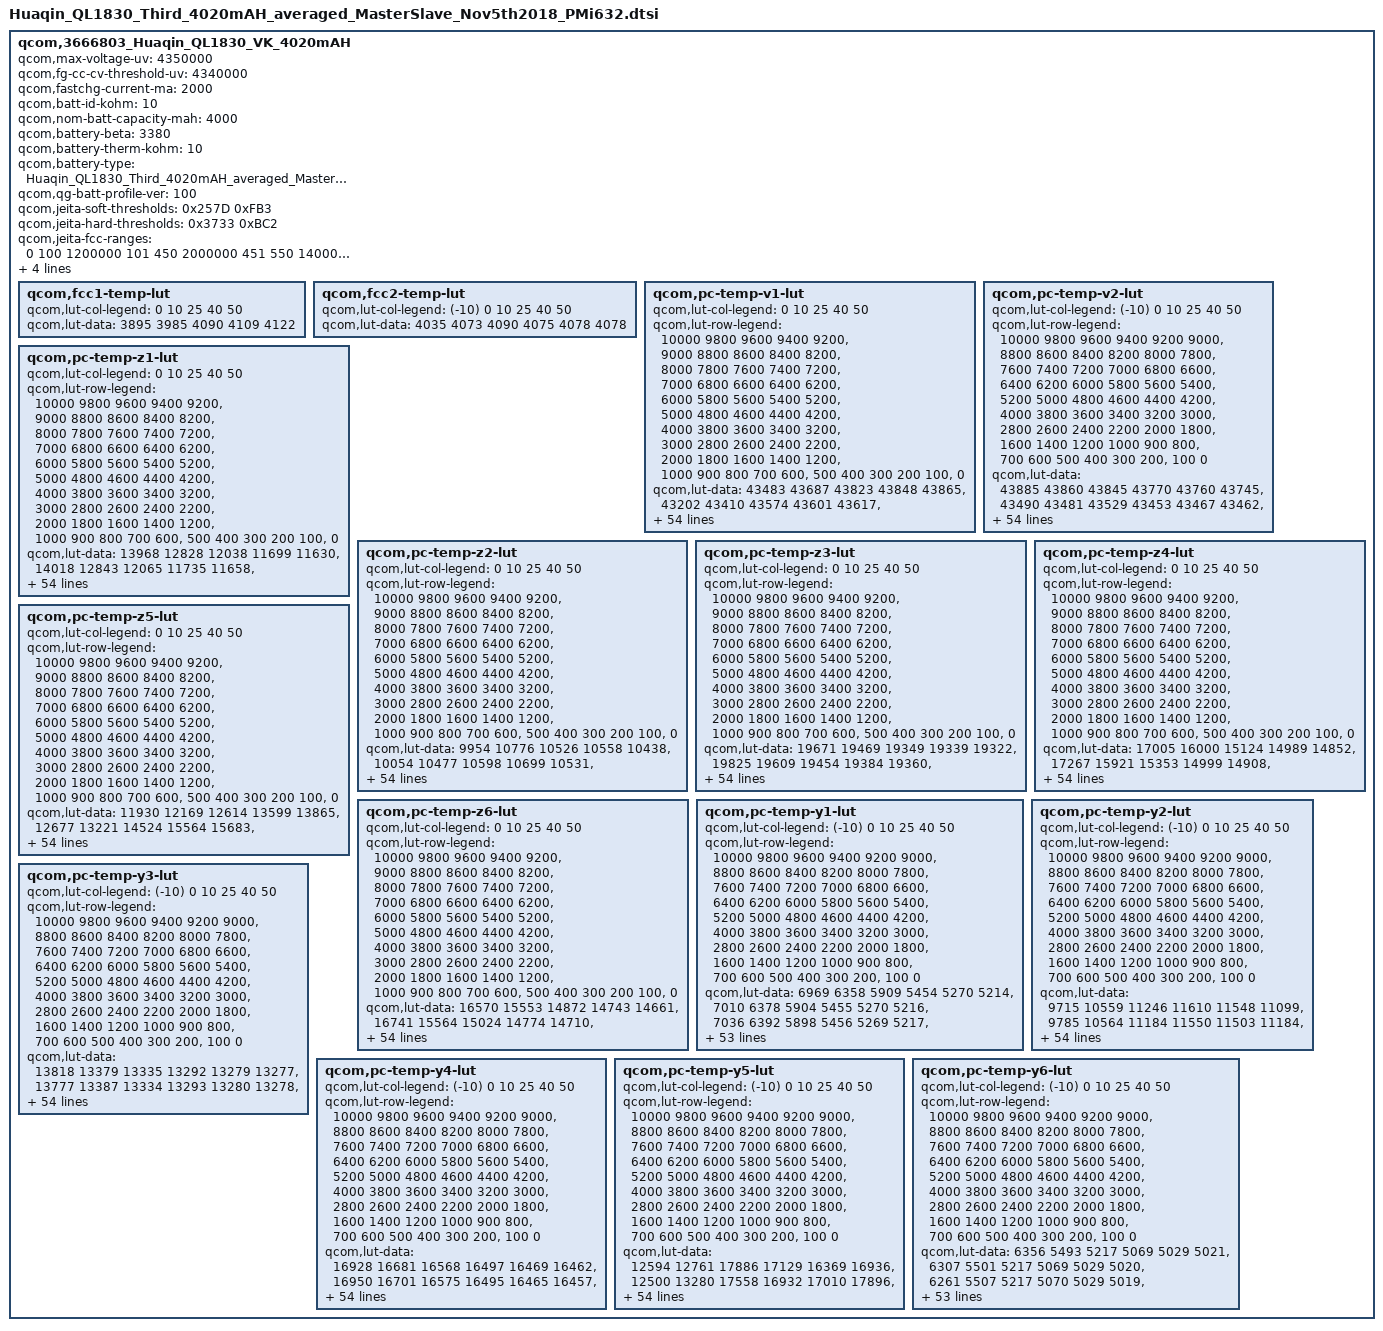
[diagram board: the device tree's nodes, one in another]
qcom,3666803_Huaqin_QL1830_VK_4020mAH {
    /* 3666803_Huaqin_QL1830_VK_4020mAH_averaged_MasterSlave_Nov5th2018 */
//huaqin add by wenyaqi for jeita and FV 4.35V at 20181105 start
    qcom,max-voltage-uv = <4350000>;
    qcom,fg-cc-cv-threshold-uv = <4340000>;
//huaqin add by wenyaqi for jeita and FV 4.35V at 20181105 end
    qcom,fastchg-current-ma = <2000>;
    qcom,batt-id-kohm = <10>;
    qcom,nom-batt-capacity-mah = <4000>;
    qcom,battery-beta = <3380>;
    qcom,battery-therm-kohm = <10>;
    qcom,battery-type = "Huaqin_QL1830_Third_4020mAH_averaged_MasterSlave_Nov5th2018";
    qcom,qg-batt-profile-ver = <100>;
//huaqin add by wenyaqi for jeita and FV 4.35V at 20181105 start
/* COOL = 15 DegC, WARM = 45 DegC */
    qcom,jeita-soft-thresholds = <0x257D 0xFB3>;
    /* COLD = 0 DegC, HOT = 55 DegC */
    qcom,jeita-hard-thresholds = <0x3733 0xBC2>;
    qcom,jeita-fcc-ranges = <0   100  1200000
                               101  450  2000000
                               451  550  1400000>;
    qcom,jeita-fv-ranges = <0   450  4350000
                            451 550  4100000>;
/*here step charge do not limit current*/
    qcom,step-chg-ranges = <3500000  4200000  2000000
                            4210000  4350000  2000000>;
//huaqin add by wenyaqi for jeita and FV 4.35V at 20181105 end

	qcom,fcc1-temp-lut {
		qcom,lut-col-legend = <0 10 25 40 50>;
		qcom,lut-data = <3895 3985 4090 4109 4122>;
	};

	qcom,fcc2-temp-lut {
		qcom,lut-col-legend = <(-10) 0 10 25 40 50>;
		qcom,lut-data = <4035 4073 4090 4075 4078 4078>;
	};

	qcom,pc-temp-v1-lut {
		qcom,lut-col-legend = <0 10 25 40 50>;
		qcom,lut-row-legend = <10000 9800 9600 9400 9200>,
			<9000 8800 8600 8400 8200>,
			<8000 7800 7600 7400 7200>,
			<7000 6800 6600 6400 6200>,
			<6000 5800 5600 5400 5200>,
			<5000 4800 4600 4400 4200>,
			<4000 3800 3600 3400 3200>,
			<3000 2800 2600 2400 2200>,
			<2000 1800 1600 1400 1200>,
			<1000 900 800 700 600>,
			<500 400 300 200 100>,
			<0>;
		qcom,lut-data = <43483 43687 43823 43848 43865>,
			<43202 43410 43574 43601 43617>,
			<42944 43147 43319 43352 43377>,
			<42701 42898 43068 43110 43137>,
			<42466 42660 42822 42871 42900>,
			<42241 42427 42579 42635 42665>,
			<42022 42198 42342 42401 42431>,
			<41807 41976 42110 42168 42198>,
			<41597 41757 41882 41937 41967>,
			<41401 41544 41655 41710 41739>,
			<41234 41348 41430 41485 41515>,
			<41060 41183 41224 41265 41295>,
			<40826 41005 41049 41051 41076>,
			<40527 40755 40866 40843 40864>,
			<40258 40452 40616 40634 40660>,
			<40039 40210 40331 40427 40464>,
			<39853 40026 40122 40235 40275>,
			<39713 39870 39979 40063 40095>,
			<39609 39740 39846 39900 39921>,
			<39509 39630 39701 39743 39757>,
			<39395 39509 39550 39588 39601>,
			<39280 39367 39389 39404 39420>,
			<39167 39218 39217 39153 39173>,
			<39056 39064 39034 38919 38936>,
			<38951 38905 38812 38764 38783>,
			<38855 38750 38598 38643 38666>,
			<38765 38590 38484 38542 38563>,
			<38680 38454 38416 38455 38468>,
			<38599 38371 38357 38373 38379>,
			<38523 38312 38294 38289 38289>,
			<38453 38266 38237 38210 38204>,
			<38386 38230 38185 38142 38130>,
			<38327 38199 38137 38083 38065>,
			<38278 38169 38092 38028 38005>,
			<38234 38143 38051 37978 37951>,
			<38191 38114 38012 37930 37900>,
			<38151 38084 37974 37884 37844>,
			<38108 38049 37938 37840 37787>,
			<38058 37997 37887 37784 37719>,
			<38001 37920 37802 37703 37637>,
			<37924 37827 37698 37605 37541>,
			<37805 37707 37588 37498 37434>,
			<37667 37569 37461 37375 37310>,
			<37512 37412 37304 37221 37157>,
			<37359 37277 37159 37077 37014>,
			<37244 37176 37073 36984 36923>,
			<37206 37143 37045 36956 36896>,
			<37176 37118 37032 36942 36881>,
			<37149 37095 37014 36925 36865>,
			<37107 37062 36974 36891 36829>,
			<36928 36894 36757 36709 36631>,
			<36497 36482 36337 36315 36234>,
			<35937 35934 35776 35783 35703>,
			<35180 35199 35012 35070 34992>,
			<33997 34069 33839 34011 33943>,
			<30000 30000 30000 30000 30000>;
	};

	qcom,pc-temp-v2-lut {
		qcom,lut-col-legend = <(-10) 0 10 25 40 50>;
		qcom,lut-row-legend = <10000 9800 9600 9400 9200 9000>,
			<8800 8600 8400 8200 8000 7800>,
			<7600 7400 7200 7000 6800 6600>,
			<6400 6200 6000 5800 5600 5400>,
			<5200 5000 4800 4600 4400 4200>,
			<4000 3800 3600 3400 3200 3000>,
			<2800 2600 2400 2200 2000 1800>,
			<1600 1400 1200 1000 900 800>,
			<700 600 500 400 300 200>,
			<100 0>;
		qcom,lut-data = <43885 43860 43845 43770 43760 43745>,
			<43490 43481 43529 43453 43467 43462>,
			<43135 43142 43234 43159 43192 43193>,
			<42823 42850 42963 42893 42934 42939>,
			<42548 42598 42714 42652 42694 42701>,
			<42294 42358 42474 42417 42459 42466>,
			<42064 42120 42238 42183 42225 42233>,
			<41843 41892 42008 41953 41994 42002>,
			<41593 41675 41785 41726 41766 41775>,
			<41306 41469 41568 41503 41541 41550>,
			<41089 41275 41356 41285 41320 41329>,
			<40986 41104 41153 41076 41102 41112>,
			<40897 40928 40954 40869 40889 40898>,
			<40689 40694 40762 40658 40685 40692>,
			<40236 40399 40574 40443 40487 40491>,
			<39838 40104 40346 40238 40295 40297>,
			<39602 39796 40022 40043 40106 40111>,
			<39412 39526 39718 39861 39925 39933>,
			<39248 39356 39530 39700 39759 39765>,
			<39104 39229 39385 39553 39601 39605>,
			<38961 39090 39227 39377 39421 39426>,
			<38813 38928 39051 39141 39196 39211>,
			<38669 38770 38883 38912 38977 38999>,
			<38534 38628 38737 38744 38797 38816>,
			<38404 38497 38604 38605 38638 38651>,
			<38291 38374 38484 38483 38507 38515>,
			<38197 38257 38374 38375 38398 38404>,
			<38116 38152 38273 38279 38301 38305>,
			<38046 38063 38181 38191 38212 38214>,
			<37985 37985 38094 38111 38130 38129>,
			<37929 37926 38013 38039 38057 38054>,
			<37877 37879 37934 37972 37990 37985>,
			<37828 37837 37866 37910 37926 37921>,
			<37778 37797 37811 37852 37860 37864>,
			<37729 37760 37764 37797 37795 37806>,
			<37679 37718 37723 37741 37724 37728>,
			<37626 37673 37688 37681 37647 37620>,
			<37572 37622 37647 37621 37568 37515>,
			<37516 37560 37593 37560 37489 37424>,
			<37459 37489 37531 37496 37409 37339>,
			<37399 37411 37460 37419 37328 37258>,
			<37338 37320 37374 37328 37245 37178>,
			<37272 37231 37260 37216 37139 37072>,
			<37200 37144 37130 37082 37009 36941>,
			<37115 37056 37011 36946 36873 36812>,
			<37007 36964 36939 36889 36822 36766>,
			<36943 36920 36910 36877 36810 36755>,
			<36870 36871 36890 36863 36800 36744>,
			<36787 36812 36864 36840 36778 36722>,
			<36669 36718 36798 36783 36731 36672>,
			<36477 36516 36602 36562 36535 36453>,
			<36156 36124 36167 36116 36113 36028>,
			<35658 35536 35562 35513 35547 35463>,
			<34904 34690 34727 34705 34792 34711>,
			<33674 33298 33484 33477 33679 33607>,
			<30842 29764 30363 29683 31836 31803>;
	};

	qcom,pc-temp-z1-lut {
		qcom,lut-col-legend = <0 10 25 40 50>;
		qcom,lut-row-legend = <10000 9800 9600 9400 9200>,
			<9000 8800 8600 8400 8200>,
			<8000 7800 7600 7400 7200>,
			<7000 6800 6600 6400 6200>,
			<6000 5800 5600 5400 5200>,
			<5000 4800 4600 4400 4200>,
			<4000 3800 3600 3400 3200>,
			<3000 2800 2600 2400 2200>,
			<2000 1800 1600 1400 1200>,
			<1000 900 800 700 600>,
			<500 400 300 200 100>,
			<0>;
		qcom,lut-data = <13968 12828 12038 11699 11630>,
			<14018 12843 12065 11735 11658>,
			<14014 12850 12067 11739 11663>,
			<14002 12846 12068 11743 11665>,
			<14002 12838 12066 11743 11666>,
			<14005 12837 12060 11742 11666>,
			<13996 12852 12056 11741 11667>,
			<13976 12865 12055 11741 11668>,
			<13952 12859 12054 11742 11671>,
			<13939 12846 12055 11742 11672>,
			<13937 12841 12059 11744 11672>,
			<13935 12843 12063 11745 11672>,
			<13916 12842 12067 11747 11673>,
			<13860 12819 12069 11748 11674>,
			<13803 12778 12058 11747 11675>,
			<13747 12762 12036 11745 11676>,
			<13699 12761 12030 11745 11676>,
			<13682 12762 12040 11747 11677>,
			<13678 12771 12051 11750 11678>,
			<13673 12789 12058 11751 11680>,
			<13657 12803 12063 11752 11681>,
			<13637 12815 12068 11753 11682>,
			<13636 12825 12072 11754 11683>,
			<13676 12828 12076 11755 11683>,
			<13714 12828 12081 11757 11685>,
			<13714 12831 12085 11759 11687>,
			<13702 12844 12089 11762 11689>,
			<13701 12856 12092 11765 11692>,
			<13713 12862 12096 11768 11695>,
			<13730 12872 12101 11772 11698>,
			<13758 12880 12107 11776 11701>,
			<13805 12892 12111 11780 11704>,
			<13829 12904 12115 11784 11706>,
			<13810 12906 12119 11788 11708>,
			<13782 12903 12129 11791 11710>,
			<13778 12902 12140 11794 11712>,
			<13792 12911 12147 11796 11714>,
			<13813 12925 12152 11798 11716>,
			<13844 12933 12158 11801 11718>,
			<13885 12949 12163 11804 11720>,
			<13909 12961 12169 11807 11722>,
			<13913 12973 12174 11810 11723>,
			<13911 12981 12179 11813 11725>,
			<13917 12956 12190 11816 11727>,
			<13923 12975 12195 11819 11728>,
			<13849 12983 12200 11821 11729>,
			<13896 12980 12198 11822 11730>,
			<13868 12969 12196 11823 11730>,
			<13832 12981 12195 11824 11732>,
			<13841 12976 12207 11827 11734>,
			<13892 13007 12214 11832 11737>,
			<13865 12986 12222 11840 11742>,
			<13935 13026 12248 11851 11751>,
			<13903 13104 12270 11866 11763>,
			<13903 13104 12270 11866 11763>,
			<13903 13104 12270 11866 11763>;
	};

	qcom,pc-temp-z2-lut {
		qcom,lut-col-legend = <0 10 25 40 50>;
		qcom,lut-row-legend = <10000 9800 9600 9400 9200>,
			<9000 8800 8600 8400 8200>,
			<8000 7800 7600 7400 7200>,
			<7000 6800 6600 6400 6200>,
			<6000 5800 5600 5400 5200>,
			<5000 4800 4600 4400 4200>,
			<4000 3800 3600 3400 3200>,
			<3000 2800 2600 2400 2200>,
			<2000 1800 1600 1400 1200>,
			<1000 900 800 700 600>,
			<500 400 300 200 100>,
			<0>;
		qcom,lut-data = <9954 10776 10526 10558 10438>,
			<10054 10477 10598 10699 10531>,
			<10110 10321 10609 10804 10678>,
			<10154 10311 10589 10775 10695>,
			<10167 10303 10555 10729 10681>,
			<10168 10302 10513 10663 10632>,
			<10166 10312 10507 10615 10595>,
			<10159 10321 10609 10596 10592>,
			<10147 10315 10688 10585 10593>,
			<10139 10300 10618 10589 10594>,
			<10134 10289 10499 10610 10594>,
			<10130 10282 10506 10634 10595>,
			<10123 10274 10668 10659 10601>,
			<10113 10256 10780 10678 10608>,
			<10102 10229 10703 10679 10597>,
			<10084 10221 10577 10672 10538>,
			<10064 10227 10555 10661 10502>,
			<10056 10238 10575 10611 10512>,
			<10054 10256 10604 10559 10533>,
			<10052 10286 10631 10562 10556>,
			<10051 10314 10661 10587 10585>,
			<10050 10339 10698 10639 10637>,
			<10049 10364 10751 10808 10794>,
			<10051 10399 10781 10934 10922>,
			<10053 10442 10746 10824 10854>,
			<10055 10463 10699 10616 10692>,
			<10057 10468 10687 10572 10652>,
			<10061 10471 10681 10616 10711>,
			<10072 10480 10686 10679 10756>,
			<10087 10497 10724 10783 10745>,
			<10107 10505 10766 10893 10720>,
			<10137 10503 10772 10891 10691>,
			<10160 10500 10769 10801 10640>,
			<10169 10502 10769 10753 10612>,
			<10179 10510 10776 10788 10616>,
			<10188 10521 10788 10851 10625>,
			<10197 10532 10802 10909 10676>,
			<10201 10547 10821 10975 10850>,
			<10086 10565 10841 11026 10966>,
			<9844 10588 10873 11068 11005>,
			<9764 10611 10902 11093 11026>,
			<9813 10629 10914 11088 11010>,
			<9842 10650 10924 11076 10951>,
			<9841 10691 10941 11092 10910>,
			<9846 10691 11021 11085 10887>,
			<9849 10689 11119 11045 10846>,
			<9822 10717 11109 11022 10851>,
			<9832 10785 11160 10977 10866>,
			<9824 10773 11290 10978 10888>,
			<9781 10777 11257 11067 11125>,
			<9773 10786 11304 11171 10980>,
			<9739 10657 11239 11020 10654>,
			<9630 10446 11233 10912 10546>,
			<9519 10284 11171 10811 10499>,
			<9519 10284 11171 10811 10499>,
			<9519 10284 11171 10811 10499>;
	};

	qcom,pc-temp-z3-lut {
		qcom,lut-col-legend = <0 10 25 40 50>;
		qcom,lut-row-legend = <10000 9800 9600 9400 9200>,
			<9000 8800 8600 8400 8200>,
			<8000 7800 7600 7400 7200>,
			<7000 6800 6600 6400 6200>,
			<6000 5800 5600 5400 5200>,
			<5000 4800 4600 4400 4200>,
			<4000 3800 3600 3400 3200>,
			<3000 2800 2600 2400 2200>,
			<2000 1800 1600 1400 1200>,
			<1000 900 800 700 600>,
			<500 400 300 200 100>,
			<0>;
		qcom,lut-data = <19671 19469 19349 19339 19322>,
			<19825 19609 19454 19384 19360>,
			<19827 19687 19498 19426 19390>,
			<19825 19696 19520 19440 19403>,
			<19822 19700 19525 19443 19408>,
			<19812 19700 19527 19442 19411>,
			<19804 19683 19530 19439 19413>,
			<19804 19665 19534 19435 19412>,
			<19807 19657 19532 19430 19408>,
			<19810 19651 19514 19422 19403>,
			<19814 19642 19486 19409 19394>,
			<19819 19616 19477 19399 19386>,
			<19828 19594 19478 19394 19382>,
			<19843 19605 19477 19390 19379>,
			<19850 19632 19472 19388 19372>,
			<19836 19640 19463 19387 19360>,
			<19809 19609 19454 19384 19350>,
			<19783 19572 19437 19370 19346>,
			<19755 19553 19422 19355 19343>,
			<19731 19538 19413 19350 19341>,
			<19712 19534 19407 19348 19340>,
			<19696 19541 19410 19350 19340>,
			<19687 19553 19432 19371 19351>,
			<19682 19568 19449 19388 19362>,
			<19679 19587 19450 19380 19353>,
			<19674 19597 19451 19360 19331>,
			<19668 19601 19448 19348 19324>,
			<19668 19603 19435 19340 19325>,
			<19674 19602 19426 19337 19328>,
			<19681 19598 19425 19356 19346>,
			<19691 19592 19425 19386 19374>,
			<19721 19585 19428 19391 19379>,
			<19738 19578 19435 19387 19371>,
			<19733 19570 19439 19382 19363>,
			<19726 19563 19438 19378 19354>,
			<19716 19555 19438 19373 19346>,
			<19700 19545 19436 19369 19344>,
			<19673 19536 19429 19364 19344>,
			<19591 19529 19424 19361 19343>,
			<19460 19524 19422 19358 19341>,
			<19415 19519 19420 19355 19339>,
			<19416 19514 19416 19353 19338>,
			<19414 19507 19410 19351 19337>,
			<19390 19491 19407 19350 19337>,
			<19361 19397 19398 19344 19336>,
			<19352 19339 19377 19337 19330>,
			<19347 19317 19373 19338 19329>,
			<19341 19306 19330 19328 19322>,
			<19338 19301 19315 19327 19317>,
			<19334 19298 19318 19320 19305>,
			<19336 19304 19339 19316 19317>,
			<19353 19311 19323 19321 19329>,
			<19369 19314 19317 19322 19330>,
			<19376 19312 19306 19319 19329>,
			<19376 19312 19306 19319 19329>,
			<19376 19312 19306 19319 19329>;
	};

	qcom,pc-temp-z4-lut {
		qcom,lut-col-legend = <0 10 25 40 50>;
		qcom,lut-row-legend = <10000 9800 9600 9400 9200>,
			<9000 8800 8600 8400 8200>,
			<8000 7800 7600 7400 7200>,
			<7000 6800 6600 6400 6200>,
			<6000 5800 5600 5400 5200>,
			<5000 4800 4600 4400 4200>,
			<4000 3800 3600 3400 3200>,
			<3000 2800 2600 2400 2200>,
			<2000 1800 1600 1400 1200>,
			<1000 900 800 700 600>,
			<500 400 300 200 100>,
			<0>;
		qcom,lut-data = <17005 16000 15124 14989 14852>,
			<17267 15921 15353 14999 14908>,
			<17095 15814 15273 15005 14924>,
			<16737 15660 15133 14937 14884>,
			<16444 15471 15044 14887 14847>,
			<16195 15338 14975 14850 14817>,
			<15985 15246 14914 14820 14789>,
			<15829 15171 14854 14792 14763>,
			<15704 15108 14816 14767 14740>,
			<15590 15054 14807 14753 14729>,
			<15475 15011 14801 14745 14723>,
			<15379 14978 14789 14737 14718>,
			<15323 14947 14753 14729 14709>,
			<15287 14909 14728 14720 14699>,
			<15250 14870 14738 14710 14696>,
			<15206 14851 14757 14701 14696>,
			<15162 14845 14756 14696 14694>,
			<15124 14840 14738 14696 14689>,
			<15086 14829 14724 14697 14682>,
			<15060 14811 14724 14695 14677>,
			<15050 14795 14726 14692 14673>,
			<15043 14779 14726 14695 14674>,
			<15037 14768 14725 14740 14726>,
			<15030 14767 14724 14794 14791>,
			<15024 14770 14774 14824 14818>,
			<15019 14776 14849 14845 14837>,
			<15018 14810 14859 14848 14838>,
			<15013 14845 14847 14838 14821>,
			<15000 14845 14831 14822 14794>,
			<14983 14835 14814 14783 14754>,
			<14961 14824 14794 14733 14708>,
			<14919 14810 14772 14710 14690>,
			<14886 14795 14749 14698 14682>,
			<14871 14782 14732 14693 14680>,
			<14860 14768 14720 14692 14681>,
			<14856 14758 14711 14691 14684>,
			<14854 14750 14708 14692 14687>,
			<14853 14743 14705 14695 14693>,
			<14909 14738 14705 14701 14699>,
			<15029 14735 14714 14713 14708>,
			<15069 14732 14722 14723 14716>,
			<15044 14729 14717 14719 14713>,
			<15024 14728 14709 14710 14706>,
			<15015 14731 14708 14712 14708>,
			<14942 14774 14698 14708 14704>,
			<14910 14802 14677 14684 14682>,
			<14912 14821 14670 14673 14672>,
			<14910 14823 14703 14664 14660>,
			<14907 14822 14709 14644 14641>,
			<14903 14821 14701 14645 14643>,
			<14897 14817 14701 14679 14664>,
			<14912 14832 14731 14688 14667>,
			<14922 14842 14745 14691 14668>,
			<14942 14859 14763 14697 14670>,
			<14942 14859 14763 14697 14670>,
			<14942 14859 14763 14697 14670>;
	};

	qcom,pc-temp-z5-lut {
		qcom,lut-col-legend = <0 10 25 40 50>;
		qcom,lut-row-legend = <10000 9800 9600 9400 9200>,
			<9000 8800 8600 8400 8200>,
			<8000 7800 7600 7400 7200>,
			<7000 6800 6600 6400 6200>,
			<6000 5800 5600 5400 5200>,
			<5000 4800 4600 4400 4200>,
			<4000 3800 3600 3400 3200>,
			<3000 2800 2600 2400 2200>,
			<2000 1800 1600 1400 1200>,
			<1000 900 800 700 600>,
			<500 400 300 200 100>,
			<0>;
		qcom,lut-data = <11930 12169 12614 13599 13865>,
			<12677 13221 14524 15564 15683>,
			<13207 13962 15397 17286 17114>,
			<13651 14363 16009 18157 18103>,
			<14101 14645 16513 18572 18776>,
			<14558 14830 17016 18734 19288>,
			<14982 14962 17603 18786 19825>,
			<15351 15118 18733 19046 20743>,
			<15690 15453 19464 19548 21746>,
			<16074 15882 19002 19619 21899>,
			<16548 15992 18334 19232 21284>,
			<17079 15786 18731 18993 20849>,
			<17679 15611 21556 19256 21301>,
			<18380 16803 23424 19794 22020>,
			<18742 19623 22471 20584 21816>,
			<18772 20525 21071 21711 20206>,
			<18772 18971 20372 22055 19235>,
			<18730 17441 19810 20519 19505>,
			<18582 17454 19582 18913 20045>,
			<18435 17890 19730 18886 20669>,
			<18195 18551 20148 19337 21552>,
			<17752 20494 22252 21376 23224>,
			<17421 23715 31855 33091 29060>,
			<17310 29446 38374 42461 34247>,
			<17274 38549 38478 36827 30498>,
			<17190 43375 38321 24864 20805>,
			<17121 45003 36460 19381 16607>,
			<17363 45916 29311 16856 15428>,
			<18140 45070 24481 15848 14948>,
			<18856 41664 23165 17608 17169>,
			<19401 38426 22443 21079 21626>,
			<21226 35882 22891 23469 24154>,
			<22404 33656 25093 25268 25774>,
			<22365 32055 27686 27132 26626>,
			<22275 30816 31201 29811 26848>,
			<22019 29666 34076 31939 27000>,
			<21076 28282 34460 31916 27297>,
			<19664 27165 34079 30986 27892>,
			<17024 27081 33792 29683 28069>,
			<13434 27730 32927 27094 25577>,
			<12288 28004 31772 24524 22670>,
			<12492 27610 30322 23468 21879>,
			<12580 26857 28563 22819 21417>,
			<12418 24782 27887 22117 21042>,
			<12763 17697 28265 21957 21095>,
			<12829 14069 25887 22222 21119>,
			<12644 13088 24813 23104 21642>,
			<12523 12749 16311 21033 20706>,
			<12467 12603 14629 23240 23048>,
			<12436 12561 15128 21990 20033>,
			<12628 12908 17024 17321 18232>,
			<12862 12895 14717 15758 17521>,
			<12821 12787 13893 15145 16698>,
			<12561 12409 13030 14401 15896>,
			<12561 12409 13030 14401 15896>,
			<12561 12409 13030 14401 15896>;
	};

	qcom,pc-temp-z6-lut {
		qcom,lut-col-legend = <0 10 25 40 50>;
		qcom,lut-row-legend = <10000 9800 9600 9400 9200>,
			<9000 8800 8600 8400 8200>,
			<8000 7800 7600 7400 7200>,
			<7000 6800 6600 6400 6200>,
			<6000 5800 5600 5400 5200>,
			<5000 4800 4600 4400 4200>,
			<4000 3800 3600 3400 3200>,
			<3000 2800 2600 2400 2200>,
			<2000 1800 1600 1400 1200>,
			<1000 900 800 700 600>,
			<500 400 300 200 100>,
			<0>;
		qcom,lut-data = <16570 15553 14872 14743 14661>,
			<16741 15564 15024 14774 14710>,
			<16660 15566 15007 14795 14729>,
			<16488 15524 14966 14778 14722>,
			<16345 15426 14933 14762 14713>,
			<16219 15354 14903 14745 14702>,
			<16112 15302 14877 14730 14691>,
			<16035 15259 14855 14716 14680>,
			<15974 15224 14836 14703 14669>,
			<15919 15196 14820 14692 14660>,
			<15868 15168 14806 14682 14653>,
			<15821 15138 14794 14673 14646>,
			<15781 15112 14780 14667 14640>,
			<15746 15096 14771 14661 14635>,
			<15710 15084 14768 14656 14628>,
			<15667 15070 14766 14651 14622>,
			<15624 15051 14762 14646 14616>,
			<15588 15033 14746 14638 14611>,
			<15556 15020 14734 14631 14606>,
			<15532 15009 14730 14627 14603>,
			<15518 15005 14729 14625 14601>,
			<15508 15006 14729 14628 14602>,
			<15504 15007 14738 14660 14632>,
			<15504 15011 14751 14691 14664>,
			<15505 15024 14778 14696 14669>,
			<15508 15037 14808 14697 14668>,
			<15513 15057 14811 14695 14665>,
			<15517 15073 14800 14687 14658>,
			<15519 15073 14790 14679 14651>,
			<15520 15068 14783 14673 14645>,
			<15521 15062 14776 14668 14640>,
			<15523 15055 14770 14662 14634>,
			<15524 15047 14764 14655 14628>,
			<15521 15039 14759 14650 14622>,
			<15515 15031 14756 14647 14617>,
			<15511 15025 14753 14644 14614>,
			<15508 15020 14749 14643 14614>,
			<15505 15016 14746 14642 14616>,
			<15499 15015 14745 14642 14618>,
			<15491 15015 14749 14645 14621>,
			<15485 15014 14753 14649 14623>,
			<15481 15015 14750 14647 14622>,
			<15475 15015 14745 14642 14619>,
			<15462 15011 14744 14643 14620>,
			<15417 14987 14738 14639 14617>,
			<15397 14971 14719 14625 14604>,
			<15395 14968 14714 14621 14600>,
			<15390 14965 14707 14612 14591>,
			<15392 14963 14701 14603 14581>,
			<15394 14963 14702 14599 14575>,
			<15398 14973 14714 14612 14591>,
			<15424 14988 14722 14622 14600>,
			<15452 15007 14730 14626 14604>,
			<15484 15028 14740 14631 14607>,
			<15484 15028 14740 14631 14607>,
			<15484 15028 14740 14631 14607>;
	};

	qcom,pc-temp-y1-lut {
		qcom,lut-col-legend = <(-10) 0 10 25 40 50>;
		qcom,lut-row-legend = <10000 9800 9600 9400 9200 9000>,
			<8800 8600 8400 8200 8000 7800>,
			<7600 7400 7200 7000 6800 6600>,
			<6400 6200 6000 5800 5600 5400>,
			<5200 5000 4800 4600 4400 4200>,
			<4000 3800 3600 3400 3200 3000>,
			<2800 2600 2400 2200 2000 1800>,
			<1600 1400 1200 1000 900 800>,
			<700 600 500 400 300 200>,
			<100 0>;
		qcom,lut-data = <6969 6358 5909 5454 5270 5214>,
			<7010 6378 5904 5455 5270 5216>,
			<7036 6392 5898 5456 5269 5217>,
			<7052 6401 5893 5456 5268 5218>,
			<7058 6406 5888 5455 5267 5219>,
			<7059 6407 5886 5454 5267 5219>,
			<7047 6401 5884 5453 5265 5219>,
			<7031 6393 5883 5451 5263 5218>,
			<7034 6390 5882 5450 5263 5218>,
			<7063 6391 5882 5449 5264 5218>,
			<7081 6391 5881 5448 5264 5218>,
			<7070 6388 5874 5447 5264 5218>,
			<7055 6385 5867 5446 5264 5218>,
			<7053 6385 5865 5446 5264 5218>,
			<7057 6389 5864 5446 5264 5218>,
			<7060 6393 5864 5447 5264 5219>,
			<7059 6405 5878 5454 5266 5220>,
			<7057 6420 5890 5460 5267 5221>,
			<7054 6425 5890 5460 5267 5221>,
			<7050 6431 5887 5458 5267 5221>,
			<7046 6430 5884 5458 5267 5221>,
			<7034 6415 5882 5461 5269 5223>,
			<7023 6401 5880 5464 5271 5224>,
			<7038 6395 5880 5466 5272 5225>,
			<7079 6388 5881 5467 5273 5226>,
			<7097 6385 5882 5469 5275 5227>,
			<7068 6389 5886 5471 5276 5228>,
			<7030 6394 5891 5474 5277 5230>,
			<7020 6406 5893 5478 5280 5232>,
			<7016 6423 5896 5482 5282 5233>,
			<7016 6423 5896 5486 5285 5235>,
			<7033 6407 5894 5490 5287 5236>,
			<7052 6397 5894 5492 5289 5238>,
			<7043 6394 5897 5494 5292 5240>,
			<7015 6390 5900 5496 5295 5242>,
			<7004 6394 5899 5499 5297 5244>,
			<7006 6403 5899 5504 5298 5246>,
			<7012 6407 5900 5508 5299 5247>,
			<7016 6398 5899 5509 5301 5248>,
			<7022 6389 5899 5510 5303 5249>,
			<7027 6391 5908 5513 5304 5250>,
			<7034 6393 5925 5517 5305 5252>,
			<7024 6403 5922 5519 5307 5253>,
			<7006 6419 5915 5523 5310 5255>,
			<7020 6430 5939 5533 5314 5258>,
			<7102 6445 5939 5540 5318 5260>,
			<7069 6457 5936 5538 5319 5260>,
			<7097 6432 5944 5543 5319 5261>,
			<7083 6439 5960 5548 5320 5260>,
			<7072 6458 5958 5547 5319 5261>,
			<7074 6461 5957 5551 5320 5261>,
			<7129 6457 5970 5562 5325 5265>,
			<7121 6481 5969 5578 5332 5270>,
			<7233 6528 6001 5598 5342 5277>,
			<7233 6528 6001 5598 5342 5277>,
			<7233 6528 6001 5598 5342 5277>;
	};

	qcom,pc-temp-y2-lut {
		qcom,lut-col-legend = <(-10) 0 10 25 40 50>;
		qcom,lut-row-legend = <10000 9800 9600 9400 9200 9000>,
			<8800 8600 8400 8200 8000 7800>,
			<7600 7400 7200 7000 6800 6600>,
			<6400 6200 6000 5800 5600 5400>,
			<5200 5000 4800 4600 4400 4200>,
			<4000 3800 3600 3400 3200 3000>,
			<2800 2600 2400 2200 2000 1800>,
			<1600 1400 1200 1000 900 800>,
			<700 600 500 400 300 200>,
			<100 0>;
		qcom,lut-data = <9715 10559 11246 11610 11548 11099>,
			<9785 10564 11184 11550 11503 11184>,
			<9854 10572 11119 11492 11442 11229>,
			<9920 10583 11056 11437 11378 11246>,
			<9980 10597 11004 11386 11329 11244>,
			<10032 10613 10969 11342 11308 11234>,
			<10070 10638 10943 11297 11310 11191>,
			<10109 10660 10927 11259 11314 11142>,
			<10186 10656 10927 11243 11304 11140>,
			<10339 10630 10933 11232 11276 11154>,
			<10468 10618 10937 11223 11259 11163>,
			<10554 10741 10932 11209 11259 11152>,
			<10624 10906 10929 11197 11261 11136>,
			<10657 10944 10978 11207 11260 11133>,
			<10690 10929 11110 11251 11266 11137>,
			<10720 10914 11162 11291 11286 11156>,
			<10743 10914 11156 11318 11354 11226>,
			<10762 10921 11150 11347 11441 11318>,
			<10726 10946 11161 11410 11525 11404>,
			<10488 10986 11190 11502 11614 11493>,
			<10314 11017 11216 11531 11649 11547>,
			<10294 11040 11241 11504 11645 11585>,
			<10278 11060 11265 11477 11630 11606>,
			<10168 11082 11286 11491 11584 11560>,
			<9860 11103 11304 11528 11515 11455>,
			<9714 11109 11317 11550 11504 11426>,
			<9697 11102 11327 11562 11561 11469>,
			<9688 11096 11339 11573 11637 11531>,
			<9683 11110 11356 11595 11709 11609>,
			<9680 11137 11373 11624 11781 11713>,
			<9678 11142 11380 11642 11830 11801>,
			<9676 11126 11382 11657 11871 11878>,
			<9674 11103 11380 11666 11889 11951>,
			<9672 11077 11376 11656 11873 12053>,
			<9670 11043 11369 11635 11843 12139>,
			<9668 10973 11356 11618 11809 12079>,
			<9666 10655 11331 11604 11749 11774>,
			<9665 10365 11307 11591 11716 11564>,
			<9663 10069 11285 11573 11725 11517>,
			<9662 9745 11259 11554 11736 11493>,
			<9661 9690 11225 11542 11733 11514>,
			<9660 9677 11181 11535 11706 11586>,
			<9660 9670 11123 11515 11665 11610>,
			<9659 9665 11034 11451 11649 11577>,
			<9658 9663 10984 11448 11565 11454>,
			<9659 9662 10881 11374 11413 11205>,
			<9658 9660 10821 11382 11367 11219>,
			<9658 9659 10773 11347 11393 11265>,
			<9657 9658 10761 11352 11391 11297>,
			<9657 9657 10734 11345 11403 11303>,
			<9657 9656 10556 11323 11432 11225>,
			<9656 9656 10226 11253 11320 11114>,
			<9654 9655 10083 11102 11244 10966>,
			<9653 9653 9697 10992 11129 10962>,
			<9653 9653 9697 10992 11129 10962>,
			<9653 9653 9697 10992 11129 10962>;
	};

	qcom,pc-temp-y3-lut {
		qcom,lut-col-legend = <(-10) 0 10 25 40 50>;
		qcom,lut-row-legend = <10000 9800 9600 9400 9200 9000>,
			<8800 8600 8400 8200 8000 7800>,
			<7600 7400 7200 7000 6800 6600>,
			<6400 6200 6000 5800 5600 5400>,
			<5200 5000 4800 4600 4400 4200>,
			<4000 3800 3600 3400 3200 3000>,
			<2800 2600 2400 2200 2000 1800>,
			<1600 1400 1200 1000 900 800>,
			<700 600 500 400 300 200>,
			<100 0>;
		qcom,lut-data = <13818 13379 13335 13292 13279 13277>,
			<13777 13387 13334 13293 13280 13278>,
			<13738 13397 13335 13294 13281 13279>,
			<13701 13407 13336 13295 13283 13280>,
			<13669 13416 13338 13296 13284 13281>,
			<13642 13422 13340 13297 13285 13282>,
			<13621 13425 13343 13298 13286 13283>,
			<13604 13427 13347 13299 13287 13284>,
			<13590 13432 13349 13299 13288 13285>,
			<13577 13443 13351 13300 13289 13286>,
			<13560 13450 13353 13301 13289 13286>,
			<13514 13451 13356 13305 13289 13287>,
			<13465 13447 13358 13308 13289 13287>,
			<13460 13437 13360 13309 13291 13287>,
			<13473 13417 13363 13309 13294 13287>,
			<13480 13401 13364 13310 13296 13287>,
			<13457 13389 13357 13310 13296 13289>,
			<13426 13382 13349 13311 13296 13291>,
			<13419 13382 13345 13312 13295 13291>,
			<13419 13384 13342 13314 13295 13292>,
			<13419 13384 13339 13314 13293 13292>,
			<13416 13379 13334 13308 13291 13288>,
			<13414 13373 13329 13300 13288 13284>,
			<13413 13367 13326 13296 13284 13281>,
			<13408 13361 13323 13293 13280 13277>,
			<13404 13355 13322 13292 13278 13276>,
			<13406 13351 13322 13292 13278 13276>,
			<13407 13345 13321 13292 13278 13276>,
			<13406 13338 13322 13293 13278 13276>,
			<13405 13330 13322 13295 13279 13275>,
			<13407 13327 13322 13296 13280 13276>,
			<13413 13330 13320 13297 13281 13276>,
			<13421 13333 13319 13298 13282 13277>,
			<13433 13337 13320 13298 13282 13278>,
			<13453 13343 13320 13298 13282 13279>,
			<13475 13349 13322 13298 13281 13279>,
			<13503 13355 13325 13297 13282 13278>,
			<13537 13363 13327 13296 13282 13276>,
			<13580 13373 13329 13297 13281 13276>,
			<13631 13385 13331 13297 13281 13275>,
			<13686 13398 13332 13297 13282 13276>,
			<13748 13412 13334 13298 13282 13279>,
			<13813 13441 13334 13298 13282 13279>,
			<13879 13499 13330 13296 13282 13277>,
			<13939 13550 13320 13292 13279 13275>,
			<13862 13571 13324 13293 13282 13281>,
			<13931 13636 13327 13297 13283 13282>,
			<14004 13705 13339 13301 13289 13287>,
			<14072 13796 13352 13307 13292 13289>,
			<14148 13872 13361 13311 13295 13292>,
			<14219 13956 13364 13306 13291 13286>,
			<14312 14042 13367 13307 13285 13285>,
			<14566 14156 13398 13312 13289 13286>,
			<14994 14378 13466 13324 13297 13293>,
			<14994 14378 13466 13324 13297 13293>,
			<14994 14378 13466 13324 13297 13293>;
	};

	qcom,pc-temp-y4-lut {
		qcom,lut-col-legend = <(-10) 0 10 25 40 50>;
		qcom,lut-row-legend = <10000 9800 9600 9400 9200 9000>,
			<8800 8600 8400 8200 8000 7800>,
			<7600 7400 7200 7000 6800 6600>,
			<6400 6200 6000 5800 5600 5400>,
			<5200 5000 4800 4600 4400 4200>,
			<4000 3800 3600 3400 3200 3000>,
			<2800 2600 2400 2200 2000 1800>,
			<1600 1400 1200 1000 900 800>,
			<700 600 500 400 300 200>,
			<100 0>;
		qcom,lut-data = <16928 16681 16568 16497 16469 16462>,
			<16950 16701 16575 16495 16465 16457>,
			<16979 16721 16582 16494 16462 16454>,
			<17009 16740 16589 16495 16460 16451>,
			<17032 16756 16595 16496 16459 16449>,
			<17041 16769 16600 16498 16458 16448>,
			<17040 16780 16604 16501 16459 16449>,
			<17035 16789 16608 16506 16461 16451>,
			<17020 16792 16616 16512 16464 16453>,
			<16974 16792 16632 16520 16469 16456>,
			<16948 16797 16646 16528 16475 16459>,
			<17129 16858 16653 16533 16482 16464>,
			<17390 16935 16662 16538 16491 16470>,
			<17360 16950 16695 16548 16498 16477>,
			<17023 16933 16758 16566 16503 16486>,
			<16813 16895 16777 16585 16511 16494>,
			<16804 16779 16699 16609 16524 16501>,
			<16802 16675 16620 16628 16541 16508>,
			<16803 16672 16609 16629 16562 16524>,
			<16815 16678 16604 16630 16587 16546>,
			<16820 16680 16595 16625 16592 16551>,
			<16806 16662 16574 16569 16553 16532>,
			<16788 16640 16556 16511 16509 16506>,
			<16784 16630 16550 16497 16487 16484>,
			<16791 16623 16546 16489 16471 16464>,
			<16793 16614 16543 16488 16467 16459>,
			<16791 16602 16541 16489 16470 16461>,
			<16789 16594 16540 16491 16475 16465>,
			<16790 16598 16539 16494 16480 16471>,
			<16794 16608 16537 16498 16488 16481>,
			<16798 16612 16535 16503 16498 16490>,
			<16800 16614 16531 16510 16510 16501>,
			<16803 16613 16529 16517 16517 16512>,
			<16805 16613 16530 16521 16519 16522>,
			<16808 16615 16533 16524 16520 16531>,
			<16811 16620 16538 16523 16518 16527>,
			<16818 16638 16546 16516 16503 16500>,
			<16828 16656 16553 16510 16489 16479>,
			<16836 16675 16559 16508 16480 16473>,
			<16848 16695 16565 16506 16475 16469>,
			<16865 16702 16569 16505 16476 16471>,
			<16891 16705 16573 16504 16483 16477>,
			<16916 16709 16567 16502 16484 16477>,
			<16940 16715 16560 16498 16479 16471>,
			<16932 16717 16555 16483 16458 16451>,
			<16829 16709 16558 16484 16456 16452>,
			<16838 16723 16576 16495 16473 16467>,
			<16852 16748 16595 16515 16487 16485>,
			<16866 16780 16624 16539 16510 16508>,
			<16880 16819 16663 16567 16532 16530>,
			<16872 16815 16676 16541 16501 16486>,
			<16870 16780 16652 16511 16474 16461>,
			<16945 16769 16659 16522 16474 16463>,
			<17130 16842 16709 16544 16480 16469>,
			<17130 16842 16709 16544 16480 16469>,
			<17130 16842 16709 16544 16480 16469>;
	};

	qcom,pc-temp-y5-lut {
		qcom,lut-col-legend = <(-10) 0 10 25 40 50>;
		qcom,lut-row-legend = <10000 9800 9600 9400 9200 9000>,
			<8800 8600 8400 8200 8000 7800>,
			<7600 7400 7200 7000 6800 6600>,
			<6400 6200 6000 5800 5600 5400>,
			<5200 5000 4800 4600 4400 4200>,
			<4000 3800 3600 3400 3200 3000>,
			<2800 2600 2400 2200 2000 1800>,
			<1600 1400 1200 1000 900 800>,
			<700 600 500 400 300 200>,
			<100 0>;
		qcom,lut-data = <12594 12761 17886 17129 16369 16936>,
			<12500 13280 17558 16932 17010 17896>,
			<12667 14057 17234 16704 17454 18651>,
			<13022 14904 16938 16453 17733 19193>,
			<13495 15633 16696 16189 17877 19517>,
			<14016 16055 16531 15920 17915 19616>,
			<14832 16243 16472 15611 17781 19439>,
			<15651 16441 16403 15268 17503 19098>,
			<15615 17219 16201 14883 17147 18753>,
			<14747 19450 15980 14417 16613 18348>,
			<14202 20546 15903 14232 16033 17863>,
			<14572 18816 16086 14435 15280 17219>,
			<15406 16662 16427 14678 14696 16497>,
			<17154 17649 16927 14606 14726 15744>,
			<21327 21690 17839 14299 14975 14954>,
			<23453 23388 19129 14196 15071 14690>,
			<20429 20756 21745 14951 14816 14799>,
			<16224 17978 23764 16336 14547 14969>,
			<15139 18385 23558 18728 14695 15109>,
			<15057 20002 22766 22295 15324 15270>,
			<15012 20671 21967 23473 16386 15740>,
			<14921 20392 21015 22802 19252 18213>,
			<14760 19994 20124 21777 21506 20346>,
			<14365 19599 19419 20521 20605 19990>,
			<13436 18919 18859 19127 18380 18838>,
			<12838 18410 18746 18599 17268 18022>,
			<12694 17660 18877 18389 16775 17485>,
			<12606 16683 19044 18366 16558 17045>,
			<12497 15439 19498 18964 16735 16553>,
			<12394 14108 20143 20162 17143 16089>,
			<12347 13734 20222 21175 17608 16074>,
			<12321 13992 19902 22030 18351 16288>,
			<12298 14381 19690 22800 19010 16613>,
			<12314 14892 19681 23588 19307 17721>,
			<12373 15548 19682 24233 19553 19405>,
			<12383 15923 20061 24119 20115 20094>,
			<12375 15797 21322 23029 21248 20367>,
			<12400 15510 21902 22175 21838 20435>,
			<12452 14998 21684 21799 21332 19530>,
			<12549 14328 21424 21446 20445 18192>,
			<12618 14015 21359 20942 19742 18149>,
			<12687 13530 21127 20344 19078 18889>,
			<12812 13332 20088 19795 18698 18541>,
			<13087 13264 18056 18632 18742 17937>,
			<13530 13210 15496 17237 18585 18122>,
			<13862 13421 15454 17153 18291 18704>,
			<13929 13673 15064 16950 16149 16640>,
			<14024 13728 15925 16794 17079 16917>,
			<14361 13963 16991 16952 16404 16242>,
			<14508 14231 17429 16945 16761 16684>,
			<14661 14489 17093 16581 16449 16239>,
			<14129 14124 15619 18210 16337 18156>,
			<12867 13641 15155 18414 17367 18320>,
			<11580 12721 14090 21271 22147 24411>,
			<11580 12721 14090 21271 22147 24411>,
			<11580 12721 14090 21271 22147 24411>;
	};

	qcom,pc-temp-y6-lut {
		qcom,lut-col-legend = <(-10) 0 10 25 40 50>;
		qcom,lut-row-legend = <10000 9800 9600 9400 9200 9000>,
			<8800 8600 8400 8200 8000 7800>,
			<7600 7400 7200 7000 6800 6600>,
			<6400 6200 6000 5800 5600 5400>,
			<5200 5000 4800 4600 4400 4200>,
			<4000 3800 3600 3400 3200 3000>,
			<2800 2600 2400 2200 2000 1800>,
			<1600 1400 1200 1000 900 800>,
			<700 600 500 400 300 200>,
			<100 0>;
		qcom,lut-data = <6356 5493 5217 5069 5029 5021>,
			<6307 5501 5217 5069 5029 5020>,
			<6261 5507 5217 5070 5029 5019>,
			<6218 5512 5218 5071 5029 5019>,
			<6178 5514 5218 5072 5030 5020>,
			<6143 5515 5219 5073 5031 5021>,
			<6112 5513 5220 5074 5032 5022>,
			<6084 5510 5221 5076 5033 5023>,
			<6051 5510 5223 5078 5035 5024>,
			<6009 5512 5227 5081 5037 5026>,
			<5988 5516 5231 5084 5039 5027>,
			<6005 5528 5233 5087 5041 5029>,
			<6030 5540 5235 5091 5043 5031>,
			<6019 5537 5245 5095 5046 5033>,
			<5942 5521 5264 5100 5050 5036>,
			<5885 5501 5269 5105 5054 5038>,
			<5869 5465 5244 5113 5058 5041>,
			<5858 5436 5217 5120 5062 5045>,
			<5856 5436 5211 5121 5068 5050>,
			<5856 5440 5207 5121 5074 5056>,
			<5855 5440 5202 5120 5075 5058>,
			<5851 5434 5192 5100 5062 5049>,
			<5847 5427 5184 5078 5047 5039>,
			<5846 5424 5181 5071 5037 5030>,
			<5845 5421 5179 5067 5030 5021>,
			<5845 5421 5178 5066 5028 5019>,
			<5849 5420 5179 5067 5029 5020>,
			<5858 5420 5180 5068 5030 5021>,
			<5865 5422 5181 5070 5032 5023>,
			<5874 5427 5183 5073 5035 5025>,
			<5885 5434 5184 5076 5039 5028>,
			<5898 5444 5184 5079 5043 5032>,
			<5915 5456 5184 5082 5046 5036>,
			<5934 5472 5186 5084 5047 5040>,
			<5958 5490 5190 5086 5047 5043>,
			<5986 5511 5195 5086 5046 5042>,
			<6021 5534 5202 5084 5043 5033>,
			<6060 5561 5210 5082 5039 5027>,
			<6103 5592 5217 5082 5036 5025>,
			<6152 5628 5224 5083 5035 5023>,
			<6204 5670 5234 5083 5036 5025>,
			<6261 5722 5246 5085 5038 5028>,
			<6321 5786 5254 5085 5039 5029>,
			<6383 5863 5264 5084 5037 5026>,
			<6435 5921 5264 5079 5029 5019>,
			<6369 5943 5283 5081 5032 5024>,
			<6426 6011 5305 5088 5037 5029>,
			<6487 6082 5336 5098 5046 5038>,
			<6543 6171 5372 5109 5055 5046>,
			<6608 6250 5409 5121 5063 5054>,
			<6664 6320 5434 5111 5052 5037>,
			<6749 6384 5454 5106 5041 5030>,
			<7017 6475 5537 5118 5044 5033>,
			<7490 6710 5659 5140 5053 5040>,
			<7490 6710 5659 5140 5053 5040>,
			<7490 6710 5659 5140 5053 5040>;
	};

};
